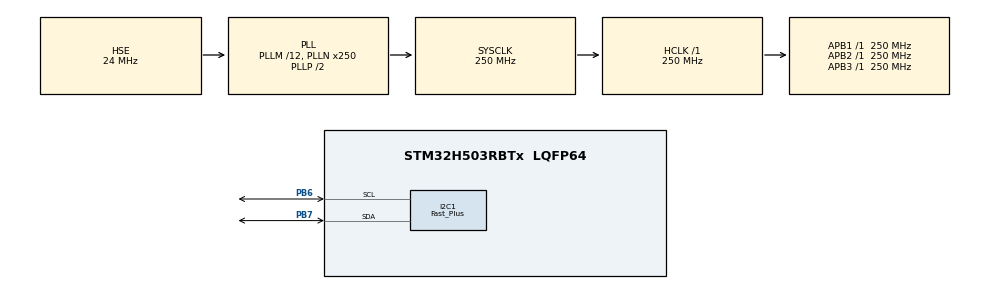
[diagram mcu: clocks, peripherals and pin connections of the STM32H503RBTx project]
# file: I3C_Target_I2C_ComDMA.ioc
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GPDMA1.DESTINC_GPDMACH0=DMA_DINC_INCREMENTED
GPDMA1.DESTINC_GPDMACH1=DMA_DINC_FIXED
GPDMA1.DIRECTION_GPDMACH1=DMA_MEMORY_TO_PERIPH
GPDMA1.IPHANDLE_GPDMACH0-SIMPLEREQUEST_GPDMACH0=__NULL
GPDMA1.IPHANDLE_GPDMACH1-SIMPLEREQUEST_GPDMACH1=__NULL
GPDMA1.REQUEST_GPDMACH0=GPDMA1_REQUEST_I2C1_RX
GPDMA1.REQUEST_GPDMACH1=GPDMA1_REQUEST_I2C1_TX
GPDMA1.SRCINC_GPDMACH1=DMA_SINC_INCREMENTED
I2C1.I2C_Fall_Time=2
I2C1.I2C_Rise_Time=26
I2C1.I2C_Speed_Mode=I2C_Fast_Plus
I2C1.NoStretchMode=I2C_NOSTRETCH_ENABLE
I2C1.OwnAddress=I2C_ADDRESS
I2C1.Timing=0x10901A4F
Mcu.Family=STM32H5
Mcu.Name=STM32H503RBTx
Mcu.Package=LQFP64
Mcu.UserConstants=I2C_ADDRESS,0xC4
NVIC.GPDMA1_Channel0_IRQn=true\:0\:0\:false\:false\:true\:false\:true\:true
NVIC.GPDMA1_Channel1_IRQn=true\:0\:0\:false\:false\:true\:false\:true\:true
NVIC.I2C1_ER_IRQn=true\:0\:0\:false\:false\:true\:true\:true\:true
NVIC.I2C1_EV_IRQn=true\:0\:0\:false\:false\:true\:true\:true\:true
NVIC.PriorityGroup=NVIC_PRIORITYGROUP_4
PB6.Mode=I2C
PB6.Signal=I2C1_SCL
PB7.Mode=I2C
PB7.Signal=I2C1_SDA
PH0-OSC_IN(PH0).Mode=HSE-External-Oscillator
PH0-OSC_IN(PH0).Signal=RCC_OSC_IN
PH1-OSC_OUT(PH1).Mode=HSE-External-Oscillator
PH1-OSC_OUT(PH1).Signal=RCC_OSC_OUT
ProjectManager.HeapSize=0x200
ProjectManager.StackSize=0x400
ProjectManager.TargetToolchain=EWARM V9.20
RCC.ADCFreq_Value=250000000
RCC.AHBFreq_Value=250000000
RCC.APB1Freq_Value=250000000
RCC.APB1TimFreq_Value=250000000
RCC.APB2Freq_Value=250000000
RCC.APB2TimFreq_Value=250000000
RCC.APB3Freq_Value=250000000
RCC.CSI_VALUE=4000000
RCC.CortexFreq_Value=250000000
RCC.EPOD_VALUE=24000000
RCC.HCLKFreq_Value=250000000
RCC.HSE_VALUE=24000000
RCC.HSI48_VALUE=48000000
RCC.HSIDiv=RCC_HSI_DIV1
RCC.HSI_VALUE=64000000
RCC.LSE_VALUE=32768
RCC.LSIRC_VALUE=32000
RCC.PLLFRACN=0
RCC.PLLM=12
RCC.PLLN=250
RCC.PLLSourceVirtual=RCC_PLL1_SOURCE_HSE
RCC.PWR_Regulator_Voltage_Scale=PWR_REGULATOR_VOLTAGE_SCALE0
RCC.SYSCLKFreq_VALUE=250000000
RCC.SYSCLKSource=RCC_SYSCLKSOURCE_PLLCLK
RCC.USBFreq_Value=48000000
RCC.VCOOutputFreq_Value=500000000
VP_GPDMA1_VS_GPDMACH0.Mode=SIMPLEREQUEST_GPDMACH0
VP_GPDMA1_VS_GPDMACH1.Mode=SIMPLEREQUEST_GPDMACH1
VP_ICACHE_VS_ICACHE.Mode=DefaultMode
VP_PWR_VS_SECSignals.Mode=Security/Privilege
board=custom

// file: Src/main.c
/* USER CODE BEGIN Header */
/**
  ******************************************************************************
  * @file    I3C/I3C_Target_I2C_ComDMA/Src/main.c
  * @author  MCD Application Team
  * @brief   This sample code shows how to use STM32H5xx I2C HAL API to transmit
  *          and receive a data buffer with a communication process based on
  *          IT transfer.
  *          The communication is done using 2 Boards.
  ******************************************************************************
  * @attention
  *
  * Copyright (c) 2023 STMicroelectronics.
  * All rights reserved.
  *
  * This software is licensed under terms that can be found in the LICENSE file
  * in the root directory of this software component.
  * If no LICENSE file comes with this software, it is provided AS-IS.
  *
  ******************************************************************************
  */
/* USER CODE END Header */
#include "main.h"

I2C_HandleTypeDef hi2c1;
DMA_HandleTypeDef handle_GPDMA1_Channel1;
DMA_HandleTypeDef handle_GPDMA1_Channel0;

/* USER CODE BEGIN PV */
/* Buffer used for transmission */
uint8_t aTxBuffer[] = " ****I2C_TwoBoards communication based on IT****  ****I2C_TwoBoards communication based on IT****  ****I2C_TwoBoards communication based on IT**** ";

/* Buffer used for reception */
uint8_t aRxBuffer[RXBUFFERSIZE];
/* USER CODE END PV */

void SystemClock_Config(void);
static void MX_GPIO_Init(void);
static void MX_GPDMA1_Init(void);
static void MX_ICACHE_Init(void);
static void MX_I2C1_Init(void);
/* USER CODE BEGIN PFP */
static uint16_t Buffercmp(uint8_t *pBuffer1, uint8_t *pBuffer2, uint16_t BufferLength);
/* USER CODE END PFP */

int main(void)
{

  /* USER CODE BEGIN 1 */
  /* STM32H5xx HAL library initialization:
       - Systick timer is configured by default as source of time base, but user
             can eventually implement his proper time base source (a general purpose
             timer for example or other time source), keeping in mind that Time base
             duration should be kept 1ms since PPP_TIMEOUT_VALUEs are defined and
             handled in milliseconds basis.
       - Set NVIC Group Priority to 4
       - Low Level Initialization
     */
  /* USER CODE END 1 */

  /* MCU Configuration--------------------------------------------------------*/

  /* Reset of all peripherals, Initializes the Flash interface and the Systick. */
  HAL_Init();

  /* Configure the system clock */
  SystemClock_Config();

  /* Initialize all configured peripherals */
  MX_GPIO_Init();
  MX_GPDMA1_Init();
  MX_ICACHE_Init();
  MX_I2C1_Init();
  /* USER CODE BEGIN 2 */
  /* Configure LED2 */
  BSP_LED_Init(LED2);

  /* The board receives the message and sends it back */

  /*##- Put I2C peripheral in reception process ###########################*/
  if (HAL_I2C_Slave_Receive_DMA(&hi2c1, (uint8_t *)aRxBuffer, RXBUFFERSIZE) != HAL_OK)
  {
    /* Transfer error in reception process */
    Error_Handler();
  }

  /*##- Wait for the end of the transfer ###################################*/
  /*  Before starting a new communication transfer, you need to check the current
      state of the peripheral; if it s busy you need to wait for the end of current
      transfer before starting a new one.
      For simplicity reasons, this example is just waiting till the end of the
      transfer, but application may perform other tasks while transfer operation
      is ongoing. */
  while (HAL_I2C_GetState(&hi2c1) != HAL_I2C_STATE_READY)
  {
  }

  /*##- Start the transmission process #####################################*/
  /* While the I2C in reception process, user can transmit data through
     "aTxBuffer" buffer */
  if (HAL_I2C_Slave_Transmit_DMA(&hi2c1, (uint8_t *)aTxBuffer, TXBUFFERSIZE) != HAL_OK)
  {
    /* Transfer error in transmission process */
    Error_Handler();
  }

  /*##- Wait for the end of the transfer ###################################*/
  /*  Before starting a new communication transfer, you need to check the current
      state of the peripheral; if it s busy you need to wait for the end of current
      transfer before starting a new one.
      For simplicity reasons, this example is just waiting till the end of the
      transfer, but application may perform other tasks while transfer operation
      is ongoing. */
  while (HAL_I2C_GetState(&hi2c1) != HAL_I2C_STATE_READY)
  {
  }

  /*##- Compare the sent and received buffers ############################*/
  if (Buffercmp((uint8_t *)aTxBuffer, (uint8_t *)aRxBuffer, RXBUFFERSIZE))
  {
    /* Processing Error */
    Error_Handler();
  }
  /* USER CODE END 2 */

  /* Infinite loop */
  while (1)
  {

  }
}

void SystemClock_Config(void)
{
  RCC_OscInitTypeDef RCC_OscInitStruct = {0};
  RCC_ClkInitTypeDef RCC_ClkInitStruct = {0};

  /** Configure the main internal regulator output voltage
  */
  __HAL_PWR_VOLTAGESCALING_CONFIG(PWR_REGULATOR_VOLTAGE_SCALE0);

  while(!__HAL_PWR_GET_FLAG(PWR_FLAG_VOSRDY)) {}

  /** Initializes the RCC Oscillators according to the specified parameters
  * in the RCC_OscInitTypeDef structure.
  */
  RCC_OscInitStruct.OscillatorType = RCC_OSCILLATORTYPE_HSE;
  RCC_OscInitStruct.HSEState = RCC_HSE_ON;
  RCC_OscInitStruct.PLL.PLLState = RCC_PLL_ON;
  RCC_OscInitStruct.PLL.PLLSource = RCC_PLL1_SOURCE_HSE;
  RCC_OscInitStruct.PLL.PLLM = 12;
  RCC_OscInitStruct.PLL.PLLN = 250;
  RCC_OscInitStruct.PLL.PLLP = 2;
  RCC_OscInitStruct.PLL.PLLQ = 2;
  RCC_OscInitStruct.PLL.PLLR = 2;
  RCC_OscInitStruct.PLL.PLLRGE = RCC_PLL1_VCIRANGE_1;
  RCC_OscInitStruct.PLL.PLLVCOSEL = RCC_PLL1_VCORANGE_WIDE;
  RCC_OscInitStruct.PLL.PLLFRACN = 0;
  if (HAL_RCC_OscConfig(&RCC_OscInitStruct) != HAL_OK)
  {
    Error_Handler();
  }

  /** Initializes the CPU, AHB and APB buses clocks
  */
  RCC_ClkInitStruct.ClockType = RCC_CLOCKTYPE_HCLK|RCC_CLOCKTYPE_SYSCLK
                              |RCC_CLOCKTYPE_PCLK1|RCC_CLOCKTYPE_PCLK2
                              |RCC_CLOCKTYPE_PCLK3;
  RCC_ClkInitStruct.SYSCLKSource = RCC_SYSCLKSOURCE_PLLCLK;
  RCC_ClkInitStruct.AHBCLKDivider = RCC_SYSCLK_DIV1;
  RCC_ClkInitStruct.APB1CLKDivider = RCC_HCLK_DIV1;
  RCC_ClkInitStruct.APB2CLKDivider = RCC_HCLK_DIV1;
  RCC_ClkInitStruct.APB3CLKDivider = RCC_HCLK_DIV1;

  if (HAL_RCC_ClockConfig(&RCC_ClkInitStruct, FLASH_LATENCY_5) != HAL_OK)
  {
    Error_Handler();
  }

  /** Configure the programming delay
  */
  __HAL_FLASH_SET_PROGRAM_DELAY(FLASH_PROGRAMMING_DELAY_2);
}

static void MX_GPDMA1_Init(void)
{

  /* Peripheral clock enable */
  __HAL_RCC_GPDMA1_CLK_ENABLE();

  /* GPDMA1 interrupt Init */
    HAL_NVIC_SetPriority(GPDMA1_Channel0_IRQn, 0, 0);
    HAL_NVIC_EnableIRQ(GPDMA1_Channel0_IRQn);
    HAL_NVIC_SetPriority(GPDMA1_Channel1_IRQn, 0, 0);
    HAL_NVIC_EnableIRQ(GPDMA1_Channel1_IRQn);

}

static void MX_I2C1_Init(void)
{

  hi2c1.Instance = I2C1;
  hi2c1.Init.Timing = 0x10901A4F;
  hi2c1.Init.OwnAddress1 = I2C_ADDRESS;
  hi2c1.Init.AddressingMode = I2C_ADDRESSINGMODE_7BIT;
  hi2c1.Init.DualAddressMode = I2C_DUALADDRESS_DISABLE;
  hi2c1.Init.OwnAddress2 = 0;
  hi2c1.Init.OwnAddress2Masks = I2C_OA2_NOMASK;
  hi2c1.Init.GeneralCallMode = I2C_GENERALCALL_DISABLE;
  hi2c1.Init.NoStretchMode = I2C_NOSTRETCH_ENABLE;
  if (HAL_I2C_Init(&hi2c1) != HAL_OK)
  {
    Error_Handler();
  }

  /** Configure Analogue filter
  */
  if (HAL_I2CEx_ConfigAnalogFilter(&hi2c1, I2C_ANALOGFILTER_ENABLE) != HAL_OK)
  {
    Error_Handler();
  }

  /** Configure Digital filter
  */
  if (HAL_I2CEx_ConfigDigitalFilter(&hi2c1, 0) != HAL_OK)
  {
    Error_Handler();
  }

  /** I2C Fast mode Plus enable
  */
  if (HAL_I2CEx_ConfigFastModePlus(&hi2c1, I2C_FASTMODEPLUS_ENABLE) != HAL_OK)
  {
    Error_Handler();
  }

}

static void MX_ICACHE_Init(void)
{

  /** Enable instruction cache (default 2-ways set associative cache)
  */
  if (HAL_ICACHE_Enable() != HAL_OK)
  {
    Error_Handler();
  }

}

static void MX_GPIO_Init(void)
{

  /* GPIO Ports Clock Enable */
  __HAL_RCC_GPIOH_CLK_ENABLE();
  __HAL_RCC_GPIOB_CLK_ENABLE();

}

/* USER CODE BEGIN 4 */
/**
  * @brief  Compares two buffers.
  * @param  pBuffer1, pBuffer2: buffers to be compared.
  * @param  BufferLength: buffer's length
  * @retval 0  : pBuffer1 identical to pBuffer2
  *         >0 : pBuffer1 differs from pBuffer2
  */
static uint16_t Buffercmp(uint8_t *pBuffer1, uint8_t *pBuffer2, uint16_t BufferLength)
{
  while (BufferLength--)
  {
    if ((*pBuffer1) != *pBuffer2)
    {
      return BufferLength;
    }
    pBuffer1++;
    pBuffer2++;
  }

  return 0;
}

/**
  * @brief  Tx Transfer completed callback.
  * @param  I2cHandle: I2C handle.
  * @note   This example shows a simple way to report end of IT Tx transfer, and
  *         you can add your own implementation.
  * @retval None
  */
void HAL_I2C_SlaveTxCpltCallback(I2C_HandleTypeDef *I2cHandle)
{
  /* Toggle LED2: Transfer in transmission process is correct */
  BSP_LED_Toggle(LED2);
}

/**
  * @brief  Rx Transfer completed callback.
  * @param  I2cHandle: I2C handle
  * @note   This example shows a simple way to report end of IT Rx transfer, and
  *         you can add your own implementation.
  * @retval None
  */
void HAL_I2C_SlaveRxCpltCallback(I2C_HandleTypeDef *I2cHandle)
{
  /* Toggle LED2: Transfer in reception process is correct */
  BSP_LED_Toggle(LED2);
}

/**
  * @brief  I2C error callbacks.
  * @param  I2cHandle: I2C handle
  * @note   This example shows a simple way to report transfer error, and you can
  *         add your own implementation.
  * @retval None
  */
void HAL_I2C_ErrorCallback(I2C_HandleTypeDef *I2cHandle)
{
  /** Error_Handler() function is called when error occurs.
    * 1- When Slave doesn't acknowledge its address, Master restarts communication.
    * 2- When Master doesn't acknowledge the last data transferred, Slave doesn't care in this example.
    */
  if (HAL_I2C_GetError(I2cHandle) != HAL_I2C_ERROR_AF)
  {
    Error_Handler();
  }
}

/* USER CODE END 4 */

void Error_Handler(void)
{
  /* USER CODE BEGIN Error_Handler_Debug */
  /* Error if LED2 is slowly blinking (1 sec. period) */
  while (1)
  {
    BSP_LED_Toggle(LED2);
    HAL_Delay(1000);
  }
  /* USER CODE END Error_Handler_Debug */
}

#ifdef  USE_FULL_ASSERT
/**
  * @brief  Reports the name of the source file and the source line number
  *         where the assert_param error has occurred.
  * @param  file: pointer to the source file name
  * @param  line: assert_param error line source number
  * @retval None
  */
void assert_failed(uint8_t *file, uint32_t line)
{
  /* USER CODE BEGIN 6 */
  /* User can add his own implementation to report the file name and line number,
    ex: printf("Wrong parameters value: file %s on line %d\r\n", file, line) */
  Error_Handler();
  /* USER CODE END 6 */
}
#endif /* USE_FULL_ASSERT */
